# STM32L4P5 register map
File version: 1.8
CPU: CM4 r0p1, little endian, MPU, FPU, 4 interrupt priority bits
Registers are 32-bit, read-write, reset 0x0 unless marked. A register's access mark holds for its fields unless they carry their own. Offsets are from the block's base; [hi:lo] are bit positions; {n}, {i} and the like mark numbered series; 'fields as' and 'values as' point back to an identical list; <NAME> marks a mode.

## OPAMP — Operational amplifiers
Base 0x40007800
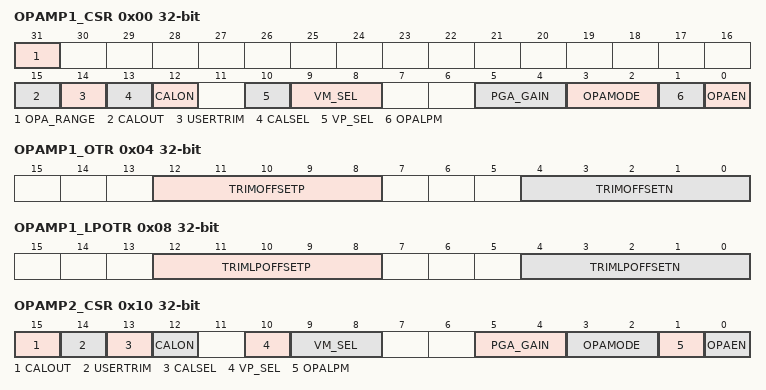
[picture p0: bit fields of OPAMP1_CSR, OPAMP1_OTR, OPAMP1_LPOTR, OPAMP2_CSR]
0x00 OPAMP1_CSR — OPAMP1 control/status register
  [31] OPA_RANGE — Operational amplifier power supply range for stability
    0=LOW (low range (VDDA < 2.4V); 1=HIGH (low range (VDDA >2.4V)
  [15] CALOUT — Operational amplifier calibration output
  [14] USERTRIM — allows to switch from AOP offset trimmed values to AOP offset
    0=Factory trim used; 1=User trim used
  [13] CALSEL — Calibration selection
    0=NMOS (0.2V applied to OPAMP inputs during calibration); 1=PMOS (VDDA-0.2V applied to OPAMP inputs during calibration")
  [12] CALON — Calibration mode enabled
    0=Disabled (Normal mode); 1=Enabled (Calibration mode)
  [10] VP_SEL — Non inverted input selection
    0=GPIO (GPIO connected to VINP); 1=DAC (DAC connected to VPINP)
  [9:8] VM_SEL — Inverting input selection
    0=GPIO (GPIO connectet to VINM); 1=LOW_LEAKAGE (Low leakage inputs connected (only available in certein BGA cases); 2=PGA_MODE (OPAMP in PGA mode)
  [5:4] PGA_GAIN — Operational amplifier Programmable amplifier gain value
    0=Gain2; 1=Gain4; 2=Gain8; 3=Gain16
  [3:2] OPAMODE — Operational amplifier PGA mode
    0=PGA_DISABLED (internal PGA diabled); 2=PGA_ENABLED (internal PGA enabled, gain programmed in PGA_GAIN); 3=FOLLOWER (internal follower)
  [1] OPALPM — Operational amplifier Low Power Mode
    0=NORMAL (OpAmp in normal mode); 1=LOW (OpAmp in low power mode)
  [0] OPAEN — Operational amplifier Enable
    0=Disabled (OpAmp disabled); 1=Enabled (OpAmp enabled)
0x04 OPAMP1_OTR — OPAMP1 offset trimming register in normal mode
  [12:8] TRIMOFFSETP — Trim for PMOS differential pairs
  [4:0] TRIMOFFSETN — Trim for NMOS differential pairs
0x08 OPAMP1_LPOTR — OPAMP1 offset trimming register in low-power mode
  [12:8] TRIMLPOFFSETP — Trim for PMOS differential pairs
  [4:0] TRIMLPOFFSETN — Trim for NMOS differential pairs
0x10 OPAMP2_CSR — OPAMP2 control/status register
  [15] CALOUT — Operational amplifier calibration output
  [14] USERTRIM — allows to switch from AOP offset trimmed values to AOP offset
    0=Factory trim used; 1=User trim used
  [13] CALSEL — Calibration selection
    values as OPAMP1_CSR.CALSEL
  [12] CALON — Calibration mode enabled
    0=Disabled (Normal mode); 1=Enabled (Calibration mode)
  [10] VP_SEL — Non inverted input selection
    values as OPAMP1_CSR.VP_SEL
  [9:8] VM_SEL — Inverting input selection
    values as OPAMP1_CSR.VM_SEL
  [5:4] PGA_GAIN — Operational amplifier Programmable amplifier gain value
    0=Gain2; 1=Gain4; 2=Gain8; 3=Gain16
  [3:2] OPAMODE — Operational amplifier PGA mode
    values as OPAMP1_CSR.OPAMODE
  [1] OPALPM — Operational amplifier Low Power Mode
    values as OPAMP1_CSR.OPALPM
  [0] OPAEN — Operational amplifier Enable
    0=Disabled (OpAmp disabled); 1=Enabled (OpAmp enabled)
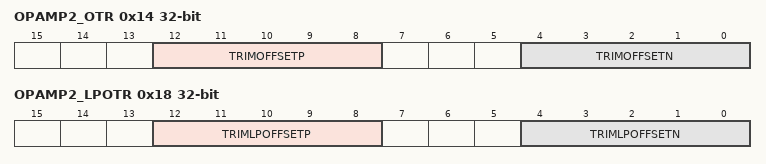
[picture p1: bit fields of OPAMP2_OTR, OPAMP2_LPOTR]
0x14 OPAMP2_OTR — OPAMP2 offset trimming register in normal mode
  fields as OPAMP1_OTR
0x18 OPAMP2_LPOTR — OPAMP2 offset trimming register in low-power mode
  fields as OPAMP1_LPOTR

## CRS — Clock recovery system
Base 0x40006000
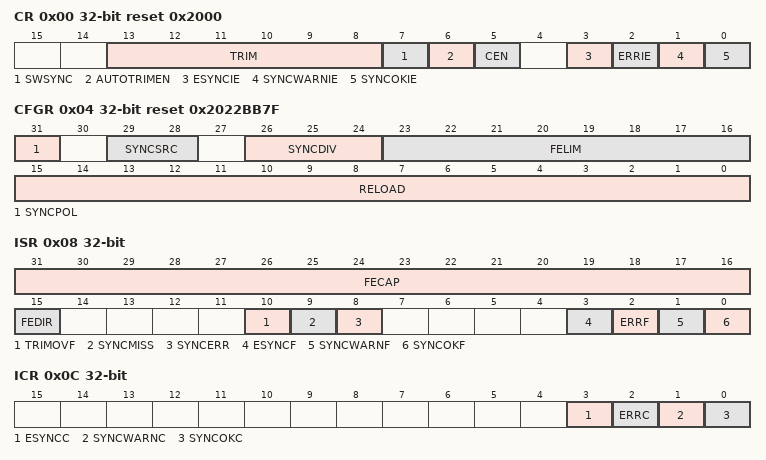
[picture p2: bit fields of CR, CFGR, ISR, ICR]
0x00 CR reset 0x2000 — control register
  [13:8] TRIM — HSI48 oscillator smooth trimming
  [7] SWSYNC — Generate software SYNC event
    1=Sync (A software sync is generated)
  [6] AUTOTRIMEN — Automatic trimming enable
    0=Disabled (Automatic trimming disabled); 1=Enabled (Automatic trimming enabled)
  [5] CEN — Frequency error counter enable
    0=Disabled (Frequency error counter disabled); 1=Enabled (Frequency error counter enabled)
  [3] ESYNCIE — Expected SYNC interrupt enable
    0=Disabled (Interrupt disabled); 1=Enabled (Interrupt enabled)
  [2] ERRIE — Synchronization or trimming error interrupt enable
    values as ESYNCIE
  [1] SYNCWARNIE — SYNC warning interrupt enable
    values as ESYNCIE
  [0] SYNCOKIE — SYNC event OK interrupt enable
    values as ESYNCIE
0x04 CFGR reset 0x2022BB7F — configuration register
  [31] SYNCPOL — SYNC polarity selection
    0=RisingEdge (SYNC active on rising edge); 1=FallingEdge (SYNC active on falling edge)
  [29:28] SYNCSRC — SYNC signal source selection
    0=GPIO_AF (GPIO AF (crs_sync_in_1) selected as SYNC signal source); 1=LSE (LSE (crs_sync_in_2) selected as SYNC signal source); 2=USB_SOF (USB SOF (crs_sync_in_3) selected as SYNC signal source)
  [26:24] SYNCDIV — SYNC divider
    0=Div1 (SYNC not divided); 1=Div2 (SYNC divided by 2); 2=Div4 (SYNC divided by 4); 3=Div8 (SYNC divided by 8); 4=Div16 (SYNC divided by 16); 5=Div32 (SYNC divided by 32); 6=Div64 (SYNC divided by 64); 7=Div128 (SYNC divided by 128)
  [23:16] FELIM — Frequency error limit
  [15:0] RELOAD — Counter reload value
0x08 ISR ro — interrupt and status register
  [31:16] FECAP — Frequency error capture
  [15] FEDIR — Frequency error direction
    0=UpCounting (Error in up-counting direction); 1=DownCounting (Error in down-counting direction)
  [10] TRIMOVF — Trimming overflow or underflow
    0=NotSignaled (Signal not set); 1=Signaled (Signal set)
  [9] SYNCMISS — SYNC missed
    0=NotSignaled (Signal not set); 1=Signaled (Signal set)
  [8] SYNCERR — SYNC error
    0=NotSignaled (Signal not set); 1=Signaled (Signal set)
  [3] ESYNCF — Expected SYNC flag
    0=NotSignaled (Signal not set); 1=Signaled (Signal set)
  [2] ERRF — Error flag
    0=NotSignaled (Signal not set); 1=Signaled (Signal set)
  [1] SYNCWARNF — SYNC warning flag
    0=NotSignaled (Signal not set); 1=Signaled (Signal set)
  [0] SYNCOKF — SYNC event OK flag
    0=NotSignaled (Signal not set); 1=Signaled (Signal set)
0x0C ICR — interrupt flag clear register
  [all] fields
    1=Clear flag
  [3] ESYNCC — Expected SYNC clear flag
  [2] ERRC — Error clear flag
  [1] SYNCWARNC — SYNC warning clear flag
  [0] SYNCOKC — SYNC event OK clear flag

## HASH — Hash processor
Base 0x50060400
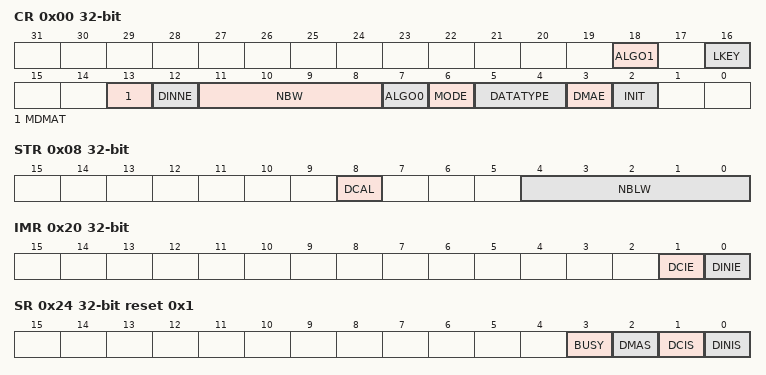
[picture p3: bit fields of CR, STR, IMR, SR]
0x00 CR access per field — control register
  [18] ALGO1 rw — ALGO
  [16] LKEY rw — Long key selection
  [13] MDMAT rw — Multiple DMA Transfers
  [12] DINNE ro — DIN not empty
  [11:8] NBW ro — Number of words already pushed
  [7] ALGO0 rw — Algorithm selection
  [6] MODE rw — Mode selection
  [5:4] DATATYPE rw — Data type selection
  [3] DMAE rw — DMA enable
  [2] INIT wo — Initialize message digest calculation
0x04 DIN — data input register
  [31:0] DATAIN — Data input
0x08 STR access per field — start register
  [8] DCAL wo — Digest calculation
  [4:0] NBLW rw — Number of valid bits in the last word of the message
{0xC+4i} HRA{i} (i=0..4) ro — HASH digest register alias {i}
  [31:0] H — H0
0x20 IMR — interrupt enable register
  [1] DCIE — Digest calculation completion interrupt enable
  [0] DINIE — Data input interrupt enable
0x24 SR access per field reset 0x1 — status register
  [3] BUSY ro — Busy bit
  [2] DMAS ro — DMA Status
  [1] DCIS rw — Digest calculation completion interrupt status
  [0] DINIS rw — Data input interrupt status
{0xF8+4i} CSR{i} (i=0..53) — HASH context swap register {i}
  [31:0] CS — CSR0
{0x310+4i} HR{i} (i=0..7) ro — HASH digest register {i}
  [31:0] H — H0

## OCTOSPIM — OctoSPI IO Manager
Base 0x50061C00
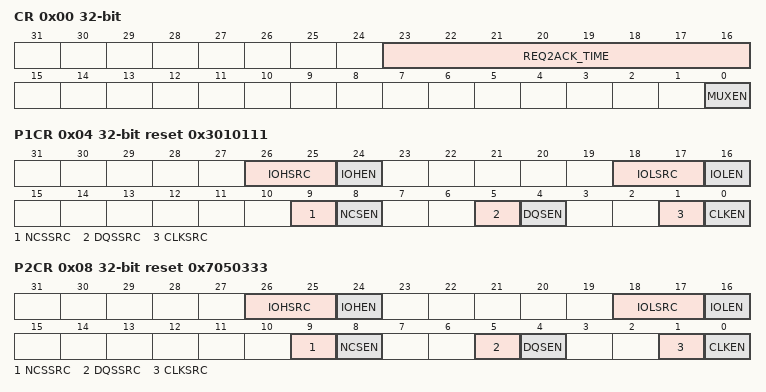
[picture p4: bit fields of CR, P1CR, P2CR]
0x00 CR access not given — configuration register
  [23:16] REQ2ACK_TIME — REQ to ACK time
  [0] MUXEN — Multiplexed mode enable
0x04 P1CR reset 0x3010111 — OctoSPI IO Manager Port 1 Configuration Register
  [26:25] IOHSRC — Source for Port
  [24] IOHEN — Enable for Port n
  [18:17] IOLSRC — Source for Port
  [16] IOLEN — Enable for Port
  [9] NCSSRC — CS Source for Port
  [8] NCSEN — CS Enable for Port
  [5] DQSSRC — DQS Source for Port
  [4] DQSEN — DQS Enable for Port
  [1] CLKSRC — CLK/CLK Source for Port
  [0] CLKEN — CLK/CLK Enable for Port
0x08 P2CR reset 0x7050333 — OctoSPI IO Manager Port 2 Configuration Register
  fields as P1CR
